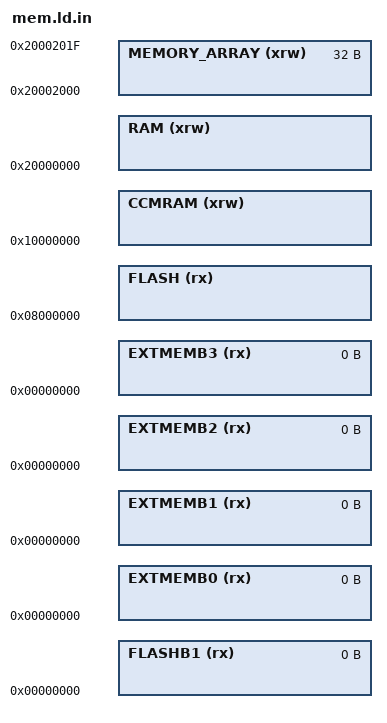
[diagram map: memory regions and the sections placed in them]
MEMORY
{
  RAM (xrw) : ORIGIN = 0x20000000, LENGTH = @STM32_RAM_SIZE@
  CCMRAM (xrw) : ORIGIN = 0x10000000, LENGTH = @STM32_CCM_SIZE@
  FLASH (rx) : ORIGIN = 0x08000000, LENGTH = @STM32_FLASH_SIZE@
  FLASHB1 (rx) : ORIGIN = 0x00000000, LENGTH = 0
  EXTMEMB0 (rx) : ORIGIN = 0x00000000, LENGTH = 0
  EXTMEMB1 (rx) : ORIGIN = 0x00000000, LENGTH = 0
  EXTMEMB2 (rx) : ORIGIN = 0x00000000, LENGTH = 0
  EXTMEMB3 (rx) : ORIGIN = 0x00000000, LENGTH = 0
  MEMORY_ARRAY (xrw)  : ORIGIN = 0x20002000, LENGTH = 32
}
